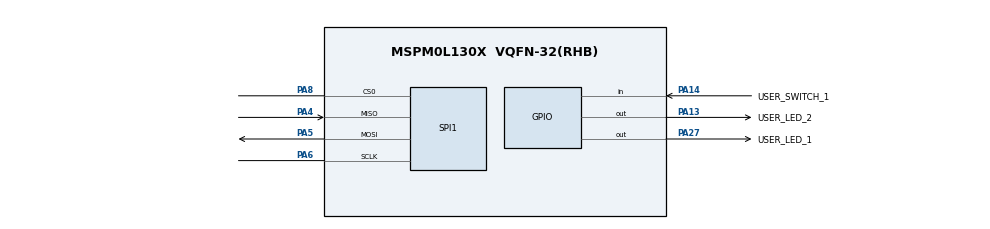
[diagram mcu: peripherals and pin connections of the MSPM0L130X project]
// @cliArgs --device "MSPM0L130X" --package "VQFN-32(RHB)" --part "Default"
// @cliArgs --board /ti/boards/LP_MSPM0L1306 --rtos nortos

/**
 * Import the modules used in this configuration.
 */
const GPIO          = scripting.addModule("/ti/driverlib/GPIO", {}, false);
const GPIO1         = GPIO.addInstance();
const GPIO2         = GPIO.addInstance();
const SPI           = scripting.addModule("/ti/driverlib/SPI", {}, false);
const SPI1          = SPI.addInstance();
const ProjectConfig = scripting.addModule("/ti/project_config/ProjectConfig");

/**
 * Write custom configuration values to the imported modules.
 */
GPIO1.$name                         = "GPIO_LEDS";
GPIO1.associatedPins.create(2);
GPIO1.associatedPins[0].$name       = "USER_LED_1";
GPIO1.associatedPins[0].pin.$assign = "PA27";
GPIO1.associatedPins[1].$name       = "USER_LED_2";
GPIO1.associatedPins[1].pin.$assign = "PA13";

const Board = scripting.addModule("/ti/driverlib/Board", {}, false);

GPIO2.$name                              = "GPIO_SWITCHES";
GPIO2.associatedPins[0].direction        = "INPUT";
GPIO2.associatedPins[0].interruptEn      = true;
GPIO2.associatedPins[0].polarity         = "FALL";
GPIO2.associatedPins[0].internalResistor = "PULL_UP";
GPIO2.associatedPins[0].$name            = "USER_SWITCH_1";
GPIO2.associatedPins[0].pin.$assign      = "PA14";

SPI1.$name                              = "SPI_0";
SPI1.mode                               = "PERIPHERAL";
SPI1.rxFifoThreshold                    = "DL_SPI_RX_FIFO_LEVEL_ONE_FRAME";
SPI1.enabledInterrupts                  = ["RX"];
SPI1.peripheral.sclkPin.$assign         = "PA6";
SPI1.peripheral.mosiPin.$assign         = "PA5";
SPI1.peripheral.misoPin.$assign         = "PA4";
SPI1.peripheral.cs0Pin.$assign          = "PA8";

const SYSCTL = scripting.addModule("/ti/driverlib/SYSCTL", {}, false);

ProjectConfig.genLinker = false;
